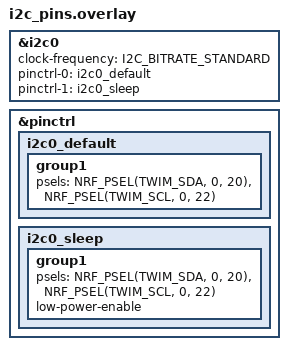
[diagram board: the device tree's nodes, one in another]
&i2c0 {
    status = "okay";
    clock-frequency = <I2C_BITRATE_STANDARD>;
    
    pinctrl-0 = <&i2c0_default>;
    pinctrl-1 = <&i2c0_sleep>;
    pinctrl-names = "default", "sleep";
};

&pinctrl {
    i2c0_default: i2c0_default {
        group1 {
            psels = <NRF_PSEL(TWIM_SDA, 0, 20)>,
                    <NRF_PSEL(TWIM_SCL, 0, 22)>;
        };
    };

    i2c0_sleep: i2c0_sleep {
        group1 {
            psels = <NRF_PSEL(TWIM_SDA, 0, 20)>,
                    <NRF_PSEL(TWIM_SCL, 0, 22)>;
            low-power-enable;
        };
    };
}; 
